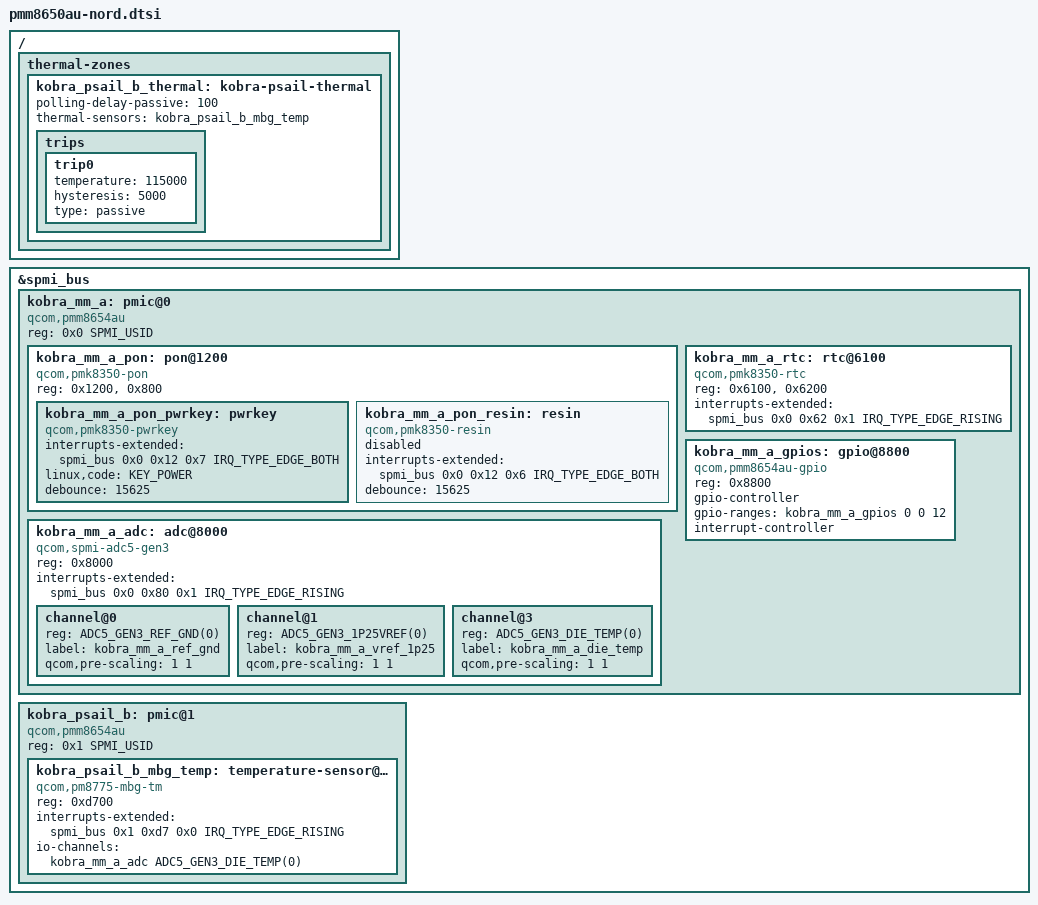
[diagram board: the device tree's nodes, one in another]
// SPDX-License-Identifier: BSD-3-Clause
/*
 * Copyright (c) Qualcomm Technologies, Inc. and/or its subsidiaries.
 */

#include <dt-bindings/interrupt-controller/irq.h>
#include <dt-bindings/spmi/spmi.h>
#include <dt-bindings/input/input.h>
#include <dt-bindings/input/linux-event-codes.h>
#include "qcom-adc5-gen3.h"

&spmi_bus {
	kobra_mm_a: pmic@0 {
		compatible = "qcom,pmm8654au", "qcom,spmi-pmic";
		reg = <0x0 SPMI_USID>;
		#address-cells = <1>;
		#size-cells = <0>;

		kobra_mm_a_pon: pon@1200 {
			compatible = "qcom,pmk8350-pon";
			reg = <0x1200>, <0x800>;
			reg-names = "hlos", "pbs";

			kobra_mm_a_pon_pwrkey: pwrkey {
				compatible = "qcom,pmk8350-pwrkey";
				interrupts-extended = <&spmi_bus 0x0 0x12 0x7 IRQ_TYPE_EDGE_BOTH>;
				linux,code = <KEY_POWER>;
				debounce = <15625>;
			};

			kobra_mm_a_pon_resin: resin {
				compatible = "qcom,pmk8350-resin";
				interrupts-extended = <&spmi_bus 0x0 0x12 0x6 IRQ_TYPE_EDGE_BOTH>;
				debounce = <15625>;
				status = "disabled";
			};
		};

		kobra_mm_a_rtc: rtc@6100 {
			compatible = "qcom,pmk8350-rtc";
			reg = <0x6100>, <0x6200>;
			reg-names = "rtc", "alarm";
			interrupts-extended = <&spmi_bus 0x0 0x62 0x1 IRQ_TYPE_EDGE_RISING>;
		};

		kobra_mm_a_adc: adc@8000 {
			compatible = "qcom,spmi-adc5-gen3";
			reg = <0x8000>;
			#address-cells = <1>;
			#size-cells = <0>;
			interrupts-extended = <&spmi_bus 0x0 0x80 0x1 IRQ_TYPE_EDGE_RISING>;
			#io-channel-cells = <1>;

			channel@0 {
				reg = <ADC5_GEN3_REF_GND(0)>;
				label = "kobra_mm_a_ref_gnd";
				qcom,pre-scaling = <1 1>;
			};

			channel@1 {
				reg = <ADC5_GEN3_1P25VREF(0)>;
				label = "kobra_mm_a_vref_1p25";
				qcom,pre-scaling = <1 1>;
			};

			channel@3 {
				reg = <ADC5_GEN3_DIE_TEMP(0)>;
				label = "kobra_mm_a_die_temp";
				qcom,pre-scaling = <1 1>;
			};
		};

		kobra_mm_a_gpios: gpio@8800 {
			compatible = "qcom,pmm8654au-gpio", "qcom,spmi-gpio";
			reg = <0x8800>;
			gpio-controller;
			gpio-ranges = <&kobra_mm_a_gpios 0 0 12>;
			#gpio-cells = <2>;
			interrupt-controller;
			#interrupt-cells = <2>;
		};
	};

	kobra_psail_b: pmic@1 {
		compatible = "qcom,pmm8654au", "qcom,spmi-pmic";
		reg = <0x1 SPMI_USID>;
		#address-cells = <1>;
		#size-cells = <0>;

		kobra_psail_b_mbg_temp: temperature-sensor@d700 {
			compatible = "qcom,pm8775-mbg-tm";
			reg = <0xd700>;
			interrupts-extended = <&spmi_bus 0x1 0xd7 0x0 IRQ_TYPE_EDGE_RISING>;
			io-channels = <&kobra_mm_a_adc ADC5_GEN3_DIE_TEMP(0)>;
			io-channel-names = "thermal";
			#thermal-sensor-cells = <0>;
		};
	};
};

/ {
	thermal-zones {
		kobra_psail_b_thermal: kobra-psail-thermal {
			polling-delay-passive = <100>;

			thermal-sensors = <&kobra_psail_b_mbg_temp>;

			trips {
				trip0 {
					temperature = <115000>;
					hysteresis = <5000>;
					type = "passive";
				};
			};
		};
	};
};

